# MCF5441x register map
Vendor: NXP; File version: 1.0
Registers are 32-bit, read-write, reset 0x0 unless marked. A register's access mark holds for its fields unless they carry their own. Offsets are from the block's base; [hi:lo] are bit positions; {n}, {i} and the like mark numbered series.

## ETHERNET
Base 0xFC0DC000
0x00 REV ro reset not defined
0x04 SCR
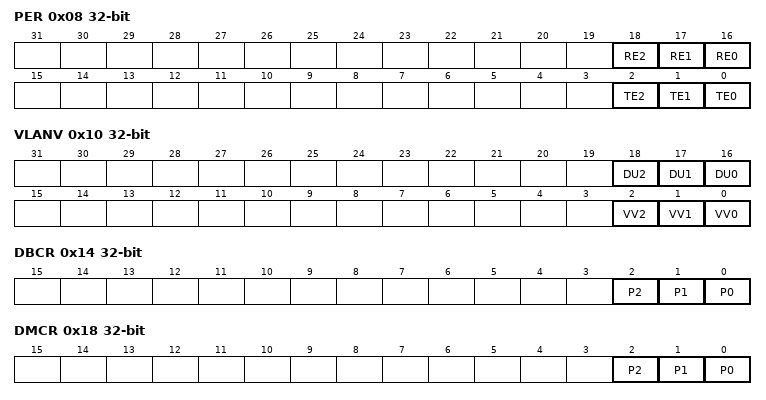
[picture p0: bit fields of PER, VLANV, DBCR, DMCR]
0x08 PER
  [18] RE2, [17] RE1, [16] RE0, [2] TE2, [1] TE1, [0] TE0
0x10 VLANV
  [18] DU2, [17] DU1, [16] DU0, [2] VV2, [1] VV1, [0] VV0
0x14 DBCR
  [2] P2, [1] P1, [0] P0
0x18 DMCR
  [2] P2, [1] P1, [0] P0
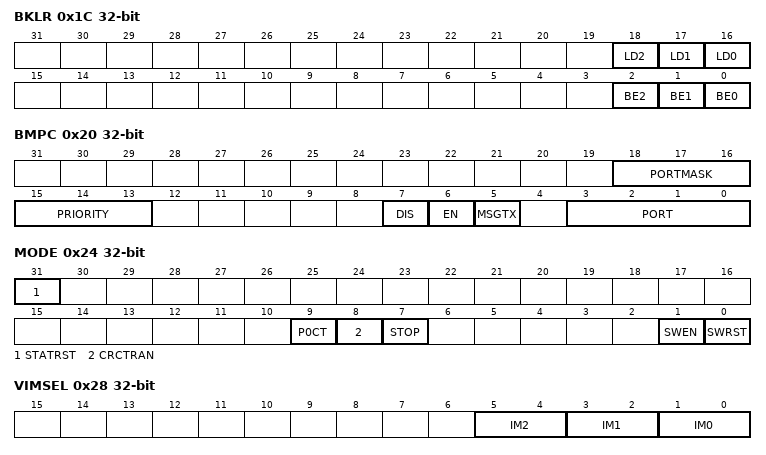
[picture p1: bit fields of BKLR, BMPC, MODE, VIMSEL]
0x1C BKLR
  [18] LD2, [17] LD1, [16] LD0, [2] BE2, [1] BE1, [0] BE0
0x20 BMPC
  [18:16] PORTMASK, [15:13] PRIORITY, [7] DIS, [6] EN, [5] MSGTX, [3:0] PORT
0x24 MODE
  [31] STATRST, [9] P0CT, [8] CRCTRAN, [7] STOP, [1] SWEN, [0] SWRST
0x28 VIMSEL
  [5:4] IM2, [3:2] IM1, [1:0] IM0
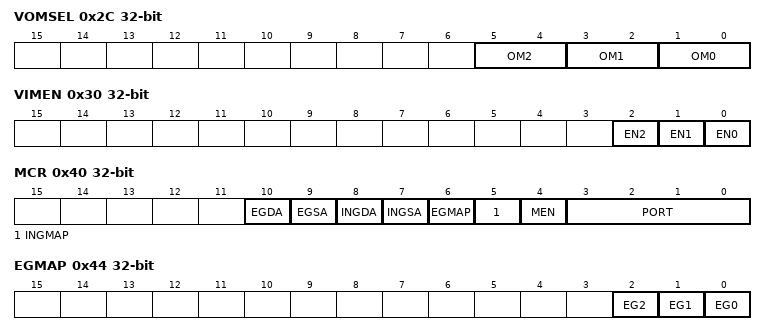
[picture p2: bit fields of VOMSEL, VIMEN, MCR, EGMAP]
0x2C VOMSEL
  [all] fields
    0=NO_OUTPUT_MANIPULATION; 1=MODE_1_STRIP_MODE; 2=MODE_2_TAG_THROUGH; 3=MODE_3_TRANSPARENT
  [5:4] OM2
  [3:2] OM1
  [1:0] OM0
0x30 VIMEN
  [2] EN2, [1] EN1, [0] EN0
0x34 VID reset 0x8100
  [31:0] TAG
0x40 MCR
  [10] EGDA
  [9] EGSA
  [8] INGDA
  [7] INGSA
  [6] EGMAP
  [5] INGMAP
  [4] MEN
    0=DISABLED; 1=ENABLED
  [3:0] PORT
0x44 EGMAP
  [2] EG2, [1] EG1, [0] EG0
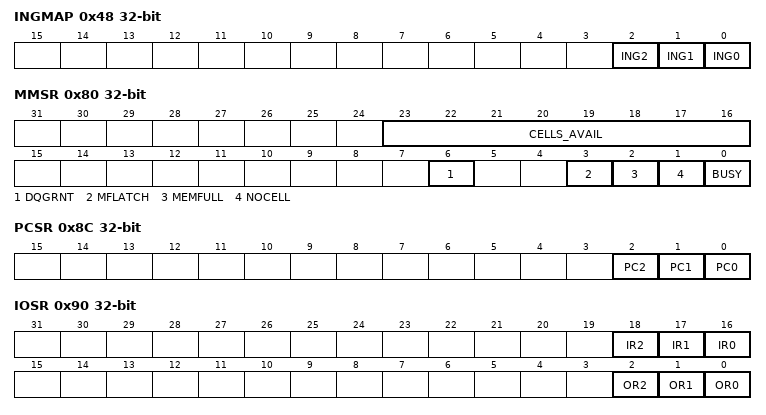
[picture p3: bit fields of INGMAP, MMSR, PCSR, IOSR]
0x48 INGMAP
  [2] ING2, [1] ING1, [0] ING0
0x4C INGSAL
  [31:0] ADDLOW
0x50 INGSAH
  [15:0] ADDHIGH
0x54 INGDAL
  [31:0] ADDLOW
0x58 INGDAH
  [15:0] ADDHIGH
0x5C EGSAL
  [31:0] ADDLOW
0x60 EGSAH
  [15:0] ADDHIGH
0x64 EGDAL
  [31:0] ADDLOW
0x68 EGDAH
  [15:0] ADDHIGH
0x6C MCVAL
  [7:0] COUNT
0x80 MMSR reset not defined
  [23:16] CELLS_AVAIL, [6] DQGRNT, [3] MFLATCH, [2] MEMFULL, [1] NOCELL, [0] BUSY
0x84 LMT reset 0x9
  [7:0] THRESH
0x88 LFC
  [31:0] COUNT
0x8C PCSR ro reset not defined
  [all] fields
    0=NOT_CONGESTED; 1=CONGESTED
  [2] PC2
  [1] PC1
  [0] PC0
0x90 IOSR ro reset not defined
  [18] IR2
    0=NOT_AVAILABLE; 1=DATA_AVAILABLE
  [17] IR1
    0=NOT_AVAILABLE; 1=DATA_AVAILABLE
  [16] IR0
    0=NOT_AVAILABLE; 1=DATA_AVAILABLE
  [2] OR2
    0=NOT_READY; 1=READY
  [1] OR1
    0=NOT_READY; 1=READY
  [0] OR0
    0=NOT_READY; 1=READY
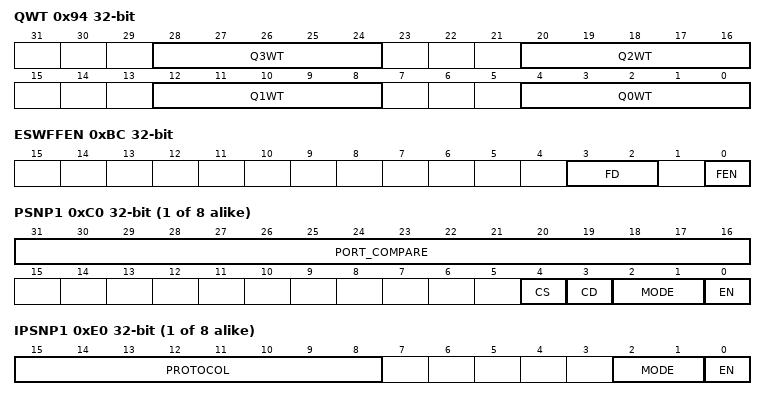
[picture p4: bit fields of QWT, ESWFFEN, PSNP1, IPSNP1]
0x94 QWT
  [8n+4:8n] Q{n}WT (n=0..3)
0x9C P0BCT reset not defined
0xBC ESWFFEN
  [3:2] FD, [0] FEN
{0xBC+4i} PSNP{i} (i=1..8)
  [31:16] PORT_COMPARE, [4] CS, [3] CD, [2:1] MODE, [0] EN
{0xDC+4i} IPSNP{i} (i=1..8)
  [15:8] PROTOCOL, [2:1] MODE, [0] EN
0x100 PVRES
  [23:0] PRIn
0x104 P1VRES reset not defined
  [23:0] PRIn
0x108 P2VRES reset not defined
  [23:0] PRIn
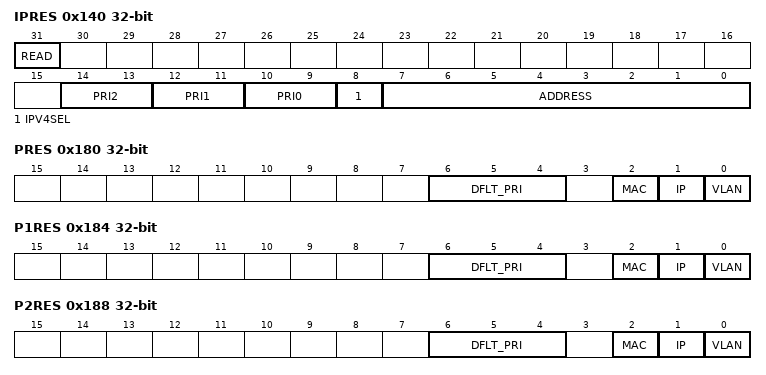
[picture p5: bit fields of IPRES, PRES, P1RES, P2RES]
0x140 IPRES
  [31] READ, [14:13] PRI2, [12:11] PRI1, [10:9] PRI0, [8] IPV4SEL, [7:0] ADDRESS
0x180 PRES
  [6:4] DFLT_PRI, [2] MAC, [1] IP, [0] VLAN
0x184 P1RES reset not defined
  [6:4] DFLT_PRI, [2] MAC, [1] IP, [0] VLAN
0x188 P2RES reset not defined
  [6:4] DFLT_PRI, [2] MAC, [1] IP, [0] VLAN
{0x200+4i} P{i}ID reset not defined (i=0..2)
  [15:0] VLANID
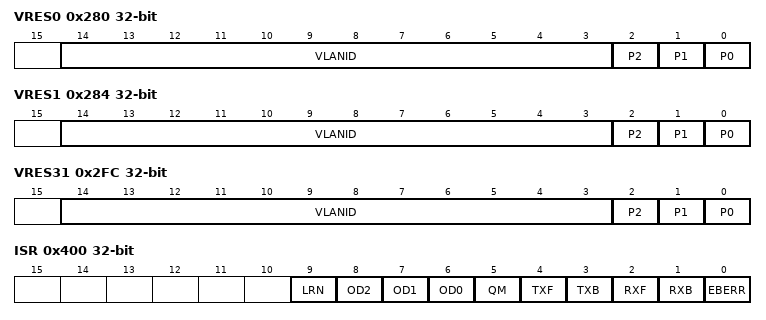
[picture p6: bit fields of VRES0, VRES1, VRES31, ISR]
0x280 VRES0
  [14:3] VLANID, [2] P2, [1] P1, [0] P0
0x284 VRES1
  [14:3] VLANID, [2] P2, [1] P1, [0] P0
{0x280+4i} VRES{i} (i=2..30)
0x2FC VRES31
  [14:3] VLANID, [2] P2, [1] P1, [0] P0
0x300 DISCN ro
0x304 DISCB ro
0x308 NDISCN ro
0x30C NDISCB ro
{0x310+0x10*i} P{i}OQC reset not defined (i=0..2)
{0x314+0x10*i} P{i}MVID reset not defined (i=0..2)
0x31C PBL ro
0x32C P1BL reset not defined
0x338 P0MVTAG reset not defined
0x33C P2BL reset not defined
0x400 ISR
  [9] LRN write-1-clears, [8] OD2 write-1-clears, [7] OD1 write-1-clears, [6] OD0 write-1-clears, [5] QM write-1-clears, [4] TXF write-1-clears, [3] TXB write-1-clears, [2] RXF write-1-clears, [1] RXB write-1-clears, [0] EBERR write-1-clears
0x404 IMR
0x408 RDSR
0x40C TDSR
0x410 MRBR
  [13:4] SIZE
0x414 RDAR
  [24] RDAR
0x418 ESWTDAR
0x500 LREC0 ro
  [31:0] MAC_ADDR0
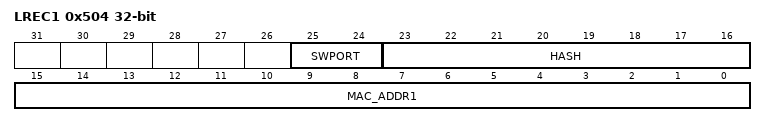
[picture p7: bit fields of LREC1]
0x504 LREC1 ro
  [25:24] SWPORT, [23:16] HASH, [15:0] MAC_ADDR1
0x508 ESWLSR ro
  [0] DA
    0=INVALID; 1=VALID

## FLEXBUS
Base 0xFC008000
{0x0+0xC*i} CSAR{i} (i=0..5)
  [31:16] BA
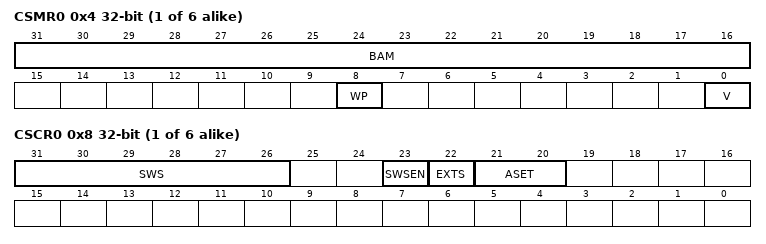
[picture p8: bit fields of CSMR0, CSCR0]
{0x4+0xC*i} CSMR{i} (i=0..5)
  [31:16] BAM
  [8] WP
  [0] V
    0=INVALID; 1=VALID
{0x8+0xC*i} CSCR{i} reset not defined (i=0..5)
  [31:26] SWS, [23] SWSEN, [22] EXTS, [21:20] ASET
